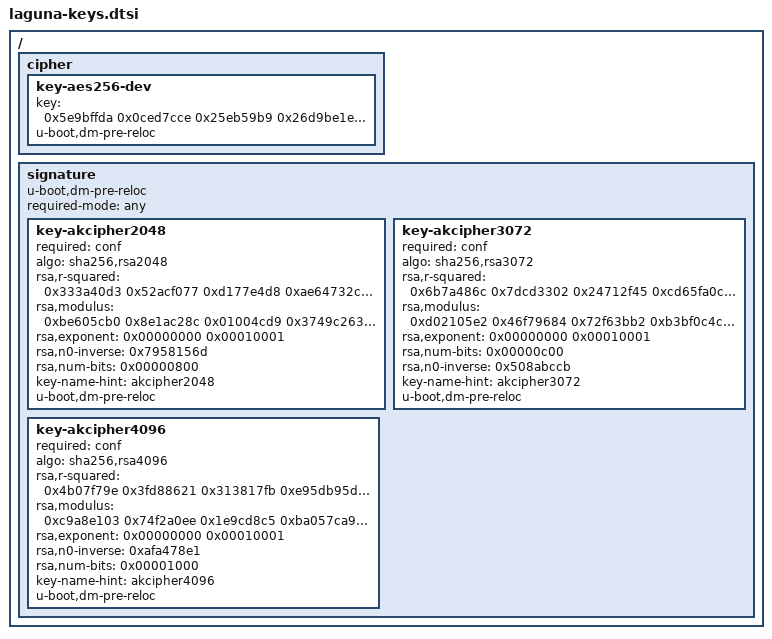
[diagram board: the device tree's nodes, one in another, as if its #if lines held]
/* SPDX-License-Identifier: GPL-2.0+
 *
 * RSA-2048/3072/4096 Public Key parameters
 *
 * Copyright (C) 2025 Charleye <wangkart@aliyun.com>
 */

/ {
#if CONFIG_IS_ENABLED(FIT_CIPHER)
	cipher {
		key-aes256-dev {
			key = <0x5e9bffda 0x0ced7cce 0x25eb59b9 0x26d9be1e
			       0x1de934bf 0xe0a61183 0x4ba8247a 0x9833453e>;
			u-boot,dm-pre-reloc;
			u-boot,dm-spl;
		};
	};
#endif

	signature {
		u-boot,dm-pre-reloc;
		u-boot,dm-spl;
		required-mode = "any";

#if CONFIG_LUA_RSA2048
		key-akcipher2048 {
			required = "conf";
#if CONFIG_LUA_SHA256
			algo = "sha256,rsa2048";
#elif CONFIG_LUA_SHA384
			algo = "sha384,rsa2048";
#elif CONFIG_LUA_SHA512
			algo = "sha512,rsa2048";
#endif
			rsa,r-squared = <0x333a40d3 0x52acf077 0xd177e4d8 0xae64732c
			                 0x18979401 0x558d1ec2 0xdac8465c 0x892cbde6
			                 0x7b30d4d7 0x556831cb 0xdadbb235 0x741a654b
			                 0x0bb1be18 0xc7da16b9 0x23eddda8 0x9a93b1ff
			                 0x43f64c42 0xd3a20eb6 0x0abef9d0 0xc733da24
			                 0x36bee7e8 0x55c31476 0x0812670d 0xddc375d0
			                 0x78b99462 0x10d2a52b 0x26214762 0x75bbb38d
			                 0xd6648238 0x976d045b 0x3ed5b5be 0xe88e3d55
			                 0xd3c22a5d 0xdc10a063 0x8925b16a 0x49e5b3f2
			                 0xe5a62b4f 0x77c70b6f 0x9f633dd4 0x02f02985
			                 0xaed5af6b 0x83ff6e60 0xa35ed3b9 0xd4883064
			                 0xcf059172 0xb3e213c3 0x1a7fb7d2 0x926c372c
			                 0xd9a4b5e4 0xe07fa61f 0x5fb2fecd 0x55a87974
			                 0x36577392 0x689b183b 0xfadab423 0xc86fd416
			                 0x423c2840 0xd21f95ad 0xa54f2e6b 0xa7e72078
			                 0xdace33e6 0x9d47765d 0xa2226669 0x8e0cb34a>;
			rsa,modulus = <0xbe605cb0 0x8e1ac28c 0x01004cd9 0x3749c263
			               0x6a52fc89 0x0f5efd24 0xc0962e96 0x7a259126
			               0x0f54b446 0x96d3d864 0x203a4f99 0x33186f60
			               0x048d55dd 0x91d82764 0x5040aaf2 0xbf08785b
			               0x2ce7346c 0xdb1bb4b5 0xd7b9ab0b 0x23c7a995
			               0x9adcffdc 0x28026882 0xf7bddf19 0xd30ba805
			               0xc4dd5f2b 0x521cdd13 0x4f3ec4a0 0xf6489f14
			               0xf160f9de 0xdefba9b8 0xdca4202f 0xa0346c83
			               0xf7cdff99 0x5afce0f6 0x6912794a 0x9c06244f
			               0x604b81dd 0x3cd55878 0x83996b33 0xc1d9c776
			               0xa34bf98b 0xdbb0dbc5 0x3c7b63fe 0xa73c8b53
			               0x8a67c9b7 0xfffc7aae 0x4391fecd 0x323413be
			               0x9b51783e 0x00ffb698 0x6eb7964d 0xb063f277
			               0xe36a0737 0xa1ddec06 0x1532890b 0x7d39de84
			               0x9a5f6e9b 0x6abb5677 0xa9f5f12c 0xd49a5720
			               0x6a0076ea 0x4af9d815 0x60f1fa0a 0xca1dc39b>;
			rsa,exponent = <0x00000000 0x00010001>;
			rsa,n0-inverse = <0x7958156d>;
			rsa,num-bits = <0x00000800>;
			key-name-hint = "akcipher2048";
			u-boot,dm-pre-reloc;
			u-boot,dm-spl;
		};
#endif

#if CONFIG_LUA_RSA3072
		key-akcipher3072 {
			required = "conf";
#if CONFIG_LUA_SHA256
			algo = "sha256,rsa3072";
#elif CONFIG_LUA_SHA384
			algo = "sha384,rsa3072";
#elif CONFIG_LUA_SHA512
			algo = "sha512,rsa3072";
#endif
			rsa,r-squared = <0x6b7a486c 0x7dcd3302 0x24712f45 0xcd65fa0c
			                 0x14e89374 0x6ff63824 0x181dad01 0xb9e2c893
			                 0xe0e625d9 0xf0c27280 0x99549293 0x14ecd4bd
			                 0xd1372734 0x94a69b23 0xbafd2e13 0x6a80c1ed
			                 0xbceb36fd 0x22bbeca5 0xe4505075 0xb9e1b00f
			                 0xda00d38e 0x2a913ae0 0x2ab4460d 0xd55fb22b
			                 0xa9e68216 0xb328bf5e 0x159ab65f 0xfa030479
			                 0x22a9f8e9 0x6fcfeb3a 0x929e89a9 0x0f0aaf58
			                 0xefb0c5b8 0x29ddc7ba 0x55a28fd2 0x42831995
			                 0x48bbfbf7 0xe8abde4e 0x2501d541 0x3141f088
			                 0x7ec0f6d7 0xd9fae8aa 0xdf2b45e9 0x9a51902e
			                 0x9b18c17e 0x1241242c 0xd27fa646 0x545720f4
			                 0xb7c8ccbd 0x5320458f 0xd89fba5c 0x969c2b59
			                 0xc4320102 0x8a9d2c3e 0x332115be 0xd842c38e
			                 0x4e56809a 0x542a7e1e 0xb8b7ff49 0x635c8433
			                 0xfd057ad9 0x0f743c59 0x2ba15bc2 0x1f325f19
			                 0x612498c5 0x05541362 0x7f7cd60b 0xdcf0417b
			                 0x1bc556b0 0xf693e85d 0x1ac59872 0xa78d6685
			                 0x3055abf9 0x522e6ce9 0xfd18aaad 0xf449ff35
			                 0x270249f5 0x13e923ce 0x2b71a96d 0xd3286098
			                 0x64b30ace 0x99772ae9 0x6482271f 0xebbf2467
			                 0xfc896940 0x8fe3280b 0x401aa368 0x0b6b0386
			                 0x82670eda 0xa101c987 0x83029ce0 0x15db4291
			                 0x6e57efdd 0x6d3c969d 0xf5eb3f08 0xf81ae1ba>;
			rsa,modulus = <0xd02105e2 0x46f79684 0x72f63bb2 0xb3bf0c4c
			               0x0ff3eead 0x39055ec8 0x9ba5c979 0xb4c78b3d
			               0x0f1e9030 0x9fa6f2dc 0x71ced74e 0x359544a6
			               0xac22bd9c 0xd295fbb0 0x01818388 0x2eac69ac
			               0xe6a4cdf6 0xb6569c60 0x42c4dd3f 0x8fccd698
			               0x15bad0b1 0x5588a128 0x5ba3b9e1 0x91b32ea7
			               0x2e49c4d1 0x28c819f0 0x2acf2944 0xaf1ebab8
			               0xc6f89f4e 0x2af0fcef 0xb112f750 0xab8a4257
			               0x38d8e8da 0x184984f6 0x735d378a 0x3d149bf0
			               0xe6fb12b2 0xf3b44ba2 0x1767edf3 0x902e1fb2
			               0x8c3ef76d 0x541c47bb 0x448b5fbb 0x6149dea1
			               0xb5bd9a1b 0x65e3b827 0x9417a157 0x02eed5e5
			               0x034d63b4 0x0affbaf7 0x531cb86d 0x55ddaafc
			               0x317384b2 0x40290b4b 0x1d8122c9 0xce37c219
			               0x3d0bf127 0x75319432 0x5c6b902c 0xb356fe18
			               0xc91f2d3f 0x4d5044c1 0xa14c9708 0xb7433bde
			               0xcd3fbcb4 0xd385e4f2 0x1f433565 0x87589ab4
			               0x677bc817 0xbd0fc76a 0xc014cb81 0xbac4ea24
			               0x3d31d96a 0x54adb8b2 0xcf263749 0x935a9c66
			               0x75cb57ec 0xed6498f2 0xf5bd9e3b 0x8cbcf48a
			               0x55b01b47 0x0fdfde6a 0xc119f25b 0x823a0dfd
			               0xded883ed 0xd804822f 0x1c9be4b4 0x89e9b198
			               0x90afcc1d 0x4b760315 0x37a69a6d 0x126aef39
			               0xe39bc5dd 0x3e599aaa 0xb99a32dd 0x3f0b371d>;
			rsa,exponent = <0x00000000 0x00010001>;
			rsa,num-bits = <0x00000c00>;
			rsa,n0-inverse = <0x508abccb>;
			key-name-hint = "akcipher3072";
			u-boot,dm-pre-reloc;
			u-boot,dm-spl;
		};
#endif

#if CONFIG_LUA_RSA4096
		key-akcipher4096 {
			required = "conf";
#if CONFIG_LUA_SHA256
			algo = "sha256,rsa4096";
#elif CONFIG_LUA_SHA384
			algo = "sha384,rsa4096";
#elif CONFIG_LUA_SHA512
			algo = "sha512,rsa4096";
#endif
			rsa,r-squared = <0x4b07f79e 0x3fd88621 0x313817fb 0xe95db95d
			                 0x3665c4bb 0xac8eeacf 0x00311840 0xbc3ceb35
			                 0x5f979d4b 0x928358a2 0xbaebd883 0xd5acfed8
			                 0x2d5ae6fb 0x98f7188a 0x191f9194 0x1acaad5d
			                 0x8baa0ab1 0x9681177c 0x0e89c5bb 0xbfeb1d3e
			                 0xbbd956b7 0xcfa3d350 0x48f9047d 0xa4e3b323
			                 0x6b2a122f 0x2de44a68 0xd6403013 0x1579a357
			                 0xa5fef862 0x0f8e17aa 0xa4b9f7c2 0xbcb2a106
			                 0x78ff35c0 0xd2bf219d 0xcaaddba5 0x71a8ca1e
			                 0x9a8be7ae 0x42a10c9c 0x33a69292 0xa13e866f
			                 0xa1f8347a 0xe5ba2a9d 0x3a4ff5a8 0x41db9bb9
			                 0x1b55fab6 0x945b3e39 0x9afc9634 0xa501b0cb
			                 0x9beb6751 0x8951e307 0xe4a1b034 0x163df620
			                 0x60458bc8 0x07350402 0xcdb954aa 0x7d78003d
			                 0x74633625 0x0e4dbad0 0xd80c3004 0x67c363e5
			                 0x084a7005 0x6f6a34fb 0x9cd05ba1 0x72e26ef1
			                 0x212555f8 0x2c79ebaf 0x97a5e173 0x30720c9b
			                 0xe2e1c34b 0xacfe0b02 0xbfda51d8 0x89fd9248
			                 0xc541e827 0x26269378 0xc5e138f6 0x14020864
			                 0x6e7c8728 0xa8e55dce 0x8900ca4a 0x01668663
			                 0xbf975033 0x38f40f78 0x7271403a 0x8685d29e
			                 0x56c2bd1f 0x5643616d 0x274e44ac 0x19d2bb0f
			                 0x91c51704 0xd867507c 0x193312eb 0x2d0c9532
			                 0x5b73e617 0xfeb5f531 0x5d32afc6 0x31bc3b11
			                 0x1776f57d 0xbd366d0e 0xce36a189 0x42d1e9ab
			                 0x880fd5ea 0x1aa4456c 0x685b2113 0x5b937bc7
			                 0x0bea4752 0x73e0d712 0x70f68032 0x2285d9b1
			                 0x3f88f626 0x443417e6 0x5e59bb68 0x0104a0b4
			                 0xb1a0847e 0x996936d2 0x0f181433 0xe9f52cef
			                 0x5efe0a82 0x0d262c6a 0xc2ecc4f6 0x89275251
			                 0x1612f761 0xed1240bf 0x5ac307b8 0x000f101f
			                 0xc5a627df 0xc9a9b117 0x91a64968 0xbdd37251>;
			rsa,modulus = <0xc9a8e103 0x74f2a0ee 0x1e9cd8c5 0xba057ca9
			               0x26a5fac5 0xae4898ff 0x829241c8 0xf0a3d3ca
			               0x98f6dc2c 0x6142bf0f 0xeac918dc 0xd47379e2
			               0x1380231c 0x6bce76ee 0xd0ef9454 0xb6df1db6
			               0x5ace7a0d 0x783bf837 0x47aa599a 0x34e19b8b
			               0x6e0712a2 0x95363ac7 0xd0544a5b 0x522ed70a
			               0x6f570587 0xa856e1a1 0x0646acaa 0x231dc02c
			               0x866d7f36 0x39113422 0xa9573f9f 0xff3e1ccf
			               0xea2a7e2b 0x1e6c3d9f 0x08ce1b56 0x7161321a
			               0xeba6fa2b 0x37fcc87b 0x2b3b49b0 0xe6dd3ab9
			               0x14a985b6 0xc4c758e9 0x95616c93 0xcc11e49b
			               0x3d6568e4 0x004e2bed 0xbae006ce 0x24903d9e
			               0x5f49c0ad 0xe92248db 0x274bdd2a 0x0e37d005
			               0x1c499163 0x6cef2895 0xb5959bd6 0x33860a81
			               0xe800e22a 0x93e893df 0x6ef4e092 0x051a62d4
			               0xda7292b1 0x5c12ff13 0xac508606 0x3a1cb01c
			               0x52e6989b 0xd4c79399 0x3790bf1b 0x69d2b192
			               0xcb173291 0x896dec9d 0xa9c1f15c 0x621073d4
			               0xf42eb502 0x772f7a46 0x7e749d06 0x2066be04
			               0xe2d12f35 0xcffa4fde 0x8c354975 0xfd193ca0
			               0xc92ef147 0x527ec9a2 0x4481c093 0xc3652345
			               0xf69e0f07 0x7601d246 0x48f734a2 0x30ca5ab6
			               0xfeedc457 0xed703104 0x8f924f81 0xa13574ab
			               0x8f7ac99e 0x50c3699d 0x4cdbeb5c 0xf00edf03
			               0x56fbc383 0xdf136474 0x52c1730d 0x59939cd1
			               0xb84a2068 0xc6f95236 0xb41013ca 0x7e4372ef
			               0x789191ef 0xc3768627 0xbd0f84b2 0x3e32388a
			               0xeec19047 0x88eda38e 0x4e48bf65 0x0b36a959
			               0x94d335d9 0xc0574f0d 0xe8af0ecb 0xb1b84d9d
			               0xe706a6ca 0x2f574c86 0x9f3df8a9 0x42b1651a
			               0x7bc54a08 0xe2009faa 0xcdd910ee 0x8ce48761
			               0x7a13f1ed 0xba7e2b5f 0xc9139cdf 0x2bcd34df>;
			rsa,exponent = <0x00000000 0x00010001>;
			rsa,n0-inverse = <0xafa478e1>;
			rsa,num-bits = <0x00001000>;
			key-name-hint = "akcipher4096";
			u-boot,dm-pre-reloc;
			u-boot,dm-spl;
		};
#endif

	};
};
